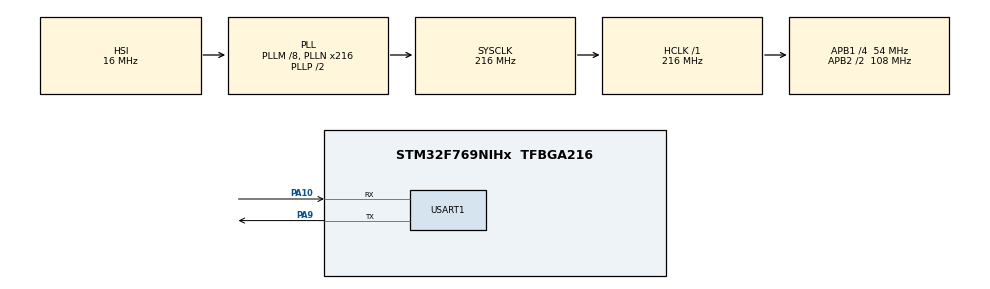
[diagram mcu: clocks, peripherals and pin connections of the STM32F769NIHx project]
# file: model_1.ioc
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CORTEX_M7.ART_ACCELERATOR_ENABLE=1
CORTEX_M7.CPU_DCache=Enabled
CORTEX_M7.CPU_ICache=Enabled
CORTEX_M7.PREFETCH_ENABLE=1
CORTEX_M7.default_mode_Activation=1
Mcu.Family=STM32F7
Mcu.Name=STM32F769NIHx
Mcu.Package=TFBGA216
NVIC.PriorityGroup=NVIC_PRIORITYGROUP_4
PA10.Mode=Asynchronous
PA10.Signal=USART1_RX
PA13.Mode=Serial_Wire
PA13.Signal=SYS_JTMS-SWDIO
PA14.Mode=Serial_Wire
PA14.Signal=SYS_JTCK-SWCLK
PA9.Mode=Asynchronous
PA9.Signal=USART1_TX
PH0/OSC_IN.Mode=HSE-External-Clock-Source
PH0/OSC_IN.Signal=RCC_OSC_IN
PH1/OSC_OUT.Mode=HSE-External-Clock-Source
PH1/OSC_OUT.Signal=RCC_OSC_OUT
ProjectManager.HeapSize=0x800
ProjectManager.StackSize=0x800
ProjectManager.TargetToolchain=STM32CubeIDE
RCC.AHBFreq_Value=216000000
RCC.APB1CLKDivider=RCC_HCLK_DIV4
RCC.APB1Freq_Value=54000000
RCC.APB1TimFreq_Value=108000000
RCC.APB2CLKDivider=RCC_HCLK_DIV2
RCC.APB2Freq_Value=108000000
RCC.APB2TimFreq_Value=216000000
RCC.CortexFreq_Value=216000000
RCC.HCLKFreq_Value=216000000
RCC.HSE_VALUE=8000000
RCC.HSI_VALUE=16000000
RCC.LSE_VALUE=32768
RCC.PLLM=8
RCC.PLLMUL=RCC_PLL_MUL9
RCC.PLLN=216
RCC.PLLQ=9
RCC.PRESCALERUSB=RCC_USBCLKSOURCE_PLL_DIV1_5
RCC.SYSCLKFreq_VALUE=216000000
RCC.SYSCLKSource=RCC_SYSCLKSOURCE_PLLCLK
RCC.SYSCLKSourceVirtual=RCC_SYSCLKSOURCE_PLLCLK
RCC.USBFreq_Value=48000000
RCC.VCOOutputFreq_Value=432000000
STMicroelectronics.X-CUBE-AI.9.0.0.ActivationBufferSizeList=120128
STMicroelectronics.X-CUBE-AI.9.0.0.ActivationBuffers=pool0
STMicroelectronics.X-CUBE-AI.9.0.0.ActivationNames=pool0
STMicroelectronics.X-CUBE-AI.9.0.0.ActivationSizes=AI_NETWORK_DATA_ACTIVATION_1_SIZE
STMicroelectronics.X-CUBE-AI.9.0.0.HeapSize=0x800
STMicroelectronics.X-CUBE-AI.9.0.0.InternalRamActivationBufferMaxSize=AI_NETWORK_DATA_ACTIVATIONS_SIZE
STMicroelectronics.X-CUBE-AI.9.0.0.LatestDirectoryUsed-00ec6f8c7ce3d0c30ca3e335a139c65a596e4951ea793adf710c689212e737b4=C\:\\Varsity\\Year of Study 4 (IE)\\Semester 2\\Investigation Project\\Project Implementation\\Code\\Experimentation\\Autoencoder
STMicroelectronics.X-CUBE-AI.9.0.0.MaximumNumberOfInputLayer=1
STMicroelectronics.X-CUBE-AI.9.0.0.MaximumNumberOfOutputLayer=1
STMicroelectronics.X-CUBE-AI.9.0.0.MaximumSizeOfInputLayer=1
STMicroelectronics.X-CUBE-AI.9.0.0.MaximumSizeOfOutputLayer=1
STMicroelectronics.X-CUBE-AI.9.0.0.ModelActualCompression-00ec6f8c7ce3d0c30ca3e335a139c65a596e4951ea793adf710c689212e737b4=0.0
STMicroelectronics.X-CUBE-AI.9.0.0.ModelCompression-00ec6f8c7ce3d0c30ca3e335a139c65a596e4951ea793adf710c689212e737b4=Medium
STMicroelectronics.X-CUBE-AI.9.0.0.ModelFlashOccupation-00ec6f8c7ce3d0c30ca3e335a139c65a596e4951ea793adf710c689212e737b4=489160
STMicroelectronics.X-CUBE-AI.9.0.0.ModelHashList=00ec6f8c7ce3d0c30ca3e335a139c65a596e4951ea793adf710c689212e737b4
STMicroelectronics.X-CUBE-AI.9.0.0.ModelKind-00ec6f8c7ce3d0c30ca3e335a139c65a596e4951ea793adf710c689212e737b4=KERAS
STMicroelectronics.X-CUBE-AI.9.0.0.ModelMacc-00ec6f8c7ce3d0c30ca3e335a139c65a596e4951ea793adf710c689212e737b4=962370
STMicroelectronics.X-CUBE-AI.9.0.0.ModelName-00ec6f8c7ce3d0c30ca3e335a139c65a596e4951ea793adf710c689212e737b4=network
STMicroelectronics.X-CUBE-AI.9.0.0.ModelNameList=network
STMicroelectronics.X-CUBE-AI.9.0.0.ModelRamOccupation-00ec6f8c7ce3d0c30ca3e335a139c65a596e4951ea793adf710c689212e737b4=120128
STMicroelectronics.X-CUBE-AI.9.0.0.ModelStructureFile-00ec6f8c7ce3d0c30ca3e335a139c65a596e4951ea793adf710c689212e737b4=C\:\\Varsity\\Year of Study 4 (IE)\\Semester 2\\Investigation Project\\Project Implementation\\Code\\Experimentation\\Autoencoder\\Cable-98-Accuracy-db-tf.keras
STMicroelectronics.X-CUBE-AI.9.0.0.ModelType-00ec6f8c7ce3d0c30ca3e335a139c65a596e4951ea793adf710c689212e737b4=STM32Cube.AI MCU runtime
STMicroelectronics.X-CUBE-AI.9.0.0.ReadyForCodeGeneration=true
STMicroelectronics.X-CUBE-AI.9.0.0.StackSize=0x800
STMicroelectronics.X-CUBE-AI.9.0.0.WorkingBufferStartAddrList=0xFFFFFFFF
STMicroelectronics.X-CUBE-AI.9.0.0.XAaCUBEAaAICcArtificialOoIntelligenceJjCore=true
STMicroelectronics.X-CUBE-AI.9.0.0.copyWeightToRam=false
STMicroelectronics.X-CUBE-AI.9.0.0.copyWeightToRam-00ec6f8c7ce3d0c30ca3e335a139c65a596e4951ea793adf710c689212e737b4=false
STMicroelectronics.X-CUBE-AI.9.0.0.customLayerConfigEnabled=false
STMicroelectronics.X-CUBE-AI.9.0.0.customLayerConfigEnabled-00ec6f8c7ce3d0c30ca3e335a139c65a596e4951ea793adf710c689212e737b4=false
STMicroelectronics.X-CUBE-AI.9.0.0.noOnnxIoTranspose=false
STMicroelectronics.X-CUBE-AI.9.0.0.noOnnxIoTranspose-00ec6f8c7ce3d0c30ca3e335a139c65a596e4951ea793adf710c689212e737b4=false
STMicroelectronics.X-CUBE-AI.9.0.0.useInputAllocation=true
STMicroelectronics.X-CUBE-AI.9.0.0.useInputAllocation-00ec6f8c7ce3d0c30ca3e335a139c65a596e4951ea793adf710c689212e737b4=true
STMicroelectronics.X-CUBE-AI.9.0.0.useOutputAllocation=true
STMicroelectronics.X-CUBE-AI.9.0.0.useOutputAllocation-00ec6f8c7ce3d0c30ca3e335a139c65a596e4951ea793adf710c689212e737b4=true
TIM14.Prescaler=107
USART1.VirtualMode-Asynchronous=VM_ASYNC
VP_CRC_VS_CRC.Mode=CRC_Activate
VP_STMicroelectronics.X-CUBE-AI_VS_ArtificialOoIntelligenceJjXAaCUBEAaAI_9.0.0.Mode=ArtificialOoIntelligenceJjXAaCUBEAaAI
VP_TIM14_VS_ClockSourceINT.Mode=Enable_Timer
board=custom

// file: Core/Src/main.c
/* USER CODE BEGIN Header */
/**
  ******************************************************************************
  * @file           : main.c
  * @brief          : Main program body
  ******************************************************************************
  * @attention
  *
  * Copyright (c) 2024 STMicroelectronics.
  * All rights reserved.
  *
  * This software is licensed under terms that can be found in the LICENSE file
  * in the root directory of this software component.
  * If no LICENSE file comes with this software, it is provided AS-IS.
  *
  ******************************************************************************
  */
/* USER CODE END Header */
#include "main.h"

/* USER CODE BEGIN Includes */
#include "network.h"
#include "network_data.h"
#include "anomaly_image_data_0.h"
#include "stdio.h"

/* USER CODE END Includes */

CRC_HandleTypeDef hcrc;

TIM_HandleTypeDef htim14;

UART_HandleTypeDef huart1;

void SystemClock_Config(void);
static void MPU_Config(void);
static void MX_GPIO_Init(void);
static void MX_CRC_Init(void);
static void MX_TIM14_Init(void);
static void MX_USART1_UART_Init(void);

/* USER CODE BEGIN 0 */

//__attribute__((section(".sdram_data"))) const float good_image_data[10][30000];

/* USER CODE END 0 */

int main(void)
{

  /* USER CODE BEGIN 1 */
	char uart_buf[50];
	int uart_buf_len = 0;
	uint16_t timer_val = 0;

  /* USER CODE END 1 */

  /* MPU Configuration--------------------------------------------------------*/
  MPU_Config();

  /* Enable the CPU Cache */

  /* Enable I-Cache---------------------------------------------------------*/
  SCB_EnableICache();

  /* Enable D-Cache---------------------------------------------------------*/
  SCB_EnableDCache();

  /* MCU Configuration--------------------------------------------------------*/

  /* Reset of all peripherals, Initializes the Flash interface and the Systick. */
  HAL_Init();

  /* Configure the system clock */
  SystemClock_Config();

  /* Initialize all configured peripherals */
  MX_GPIO_Init();
  MX_CRC_Init();
  MX_TIM14_Init();
  MX_USART1_UART_Init();
  /* USER CODE BEGIN 2 */

  // THIS IS FOR THE COMPRESSION VALUE OF LOW!!!!!!!

  static ai_handle network = AI_HANDLE_NULL;

      /* Global c-array to handle the activations buffer */
      AI_ALIGNED(32)
      static ai_u8 activations[AI_NETWORK_DATA_ACTIVATIONS_SIZE];

      /* Array to store the data of the input tensor */
      AI_ALIGNED(32)
      static ai_float in_data[AI_NETWORK_IN_1_SIZE];
      /* or static ai_u8 in_data[AI_NETWORK_IN_1_SIZE_BYTES]; */

      /* c-array to store the data of the output tensor */
      AI_ALIGNED(32)
      static ai_float out_data[AI_NETWORK_OUT_1_SIZE];
    //  static ai_u8 out_data[AI_NETWORK_OUT_1_SIZE_BYTES];

      /* Array of pointer to manage the model's input/output tensors */
      static ai_buffer *ai_input;
      static ai_buffer *ai_output;

      int aiInit(void) {
          ai_error err;

          /* Create and initialize the c-model */
          const ai_handle acts[] = { activations };
          err = ai_network_create_and_init(&network, acts, NULL);
          if (err.type != AI_ERROR_NONE) {}

          /* Reteive pointers to the model's input/output tensors */
          ai_input = ai_network_inputs_get(network, NULL);
          ai_output = ai_network_outputs_get(network, NULL);

          return 0;
        }

      int aiRun(const void *in_data, void *out_data) {
          ai_i32 n_batch;
          ai_error err;

          /* 1 - Update IO handlers with the data payload */
          ai_input[0].data = AI_HANDLE_PTR(in_data);
          ai_output[0].data = AI_HANDLE_PTR(out_data);

          /* 2 - Perform the inference */
          n_batch = ai_network_run(network, &ai_input[0], &ai_output[0]);
          if (n_batch != 1) {
              err = ai_network_get_error(network);
          };

          return 0;
        }

      int argmax(ai_float nn_output[]){

    	  if (nn_output[0] > nn_output[1]){
    		  return 0;
    	  }
    	  else{
    		  return 1;
    	  }
      }

      uint8_t counter = 0;
      int argmax_output = 0;
      float acc = 0.0;
      int true_positives = 0;
      int false_negatives = 0;

      int false_positives = 0;
      int true_negatives = 0;
      int final_outputs[3] = {0, 0, 0};

    float get_accuracy(int counter, float num_images){
    	  int count_value = counter;
    	  float accuracy = (float)(count_value/num_images);
    	  return accuracy;
      }

    void calculate_true_positives(int output[], int size){

    	for(int i = 0; i < size; i++){
    		if (output[i] == 0){
    			true_positives++;
    		}
    	}
    }

    void calculate_false_negatives(int output[], int size){

        	for(int i = 0; i < size; i++){
        		if (output[i] == 1){
        			false_negatives++;
        		}
        	}
        }

    void calculate_false_positives(int output[], int size){

            	for(int i = 0; i < size; i++){
            		if (output[i] == 0){
            			false_positives++;
            		}
            	}
            }

    void calculate_true_negatives(int output[], int size){

            	for(int i = 0; i < size; i++){
            		if (output[i] == 1){
            			true_negatives++;
            		}
            	}
            }

      aiInit();

      HAL_TIM_Base_Start(&htim14);

  /* USER CODE END 2 */

  /* Infinite loop */
  /* USER CODE BEGIN WHILE */
  while (1)
  {
	  for (int i = 0; i < 3; i++){
		  for (int j = 0; j < AI_NETWORK_IN_1_SIZE; j++){
		  	  	  		  ((ai_float*)in_data)[j] = image_data[i][j];
		  	  	  	  }

		  	  	  	  timer_val = __HAL_TIM_GET_COUNTER(&htim14);
		  	  	  	  aiRun(in_data, out_data);
		  	  	  	  timer_val = __HAL_TIM_GET_COUNTER(&htim14) - timer_val;

		  	  	  	  uart_buf_len = sprintf(uart_buf, "%u us\r\n", timer_val);
		  	  	      HAL_UART_Transmit(&huart1, (uint8_t *)uart_buf, uart_buf_len, 100);

		  	  	  	  argmax_output = argmax(out_data);
		  	  	  	  final_outputs[i] = argmax_output;

		  	  	  	  //HAL_UART_Transmit(&huart1, message, 50, HAL_MAX_DELAY);
//		  	  	  	  HAL_Delay(2000);
	  }

	  //acc = get_accuracy(counter, 5.0);

	  uart_buf_len = sprintf(uart_buf, "\r\n \r\n \r\n \r\n");
	  HAL_UART_Transmit(&huart1, (uint8_t *)uart_buf, uart_buf_len, 100);
//	  calculate_true_positives(final_outputs, 2);
//	  calculate_false_negatives(final_outputs, 2);
	  calculate_false_positives(final_outputs, 3);
	  calculate_true_negatives(final_outputs, 3);

    /* USER CODE END WHILE */

  }
}

void SystemClock_Config(void)
{
  RCC_OscInitTypeDef RCC_OscInitStruct = {0};
  RCC_ClkInitTypeDef RCC_ClkInitStruct = {0};

  /** Configure the main internal regulator output voltage
  */
  __HAL_RCC_PWR_CLK_ENABLE();
  __HAL_PWR_VOLTAGESCALING_CONFIG(PWR_REGULATOR_VOLTAGE_SCALE1);

  /** Initializes the RCC Oscillators according to the specified parameters
  * in the RCC_OscInitTypeDef structure.
  */
  RCC_OscInitStruct.OscillatorType = RCC_OSCILLATORTYPE_HSI;
  RCC_OscInitStruct.HSIState = RCC_HSI_ON;
  RCC_OscInitStruct.HSICalibrationValue = RCC_HSICALIBRATION_DEFAULT;
  RCC_OscInitStruct.PLL.PLLState = RCC_PLL_ON;
  RCC_OscInitStruct.PLL.PLLSource = RCC_PLLSOURCE_HSI;
  RCC_OscInitStruct.PLL.PLLM = 8;
  RCC_OscInitStruct.PLL.PLLN = 216;
  RCC_OscInitStruct.PLL.PLLP = RCC_PLLP_DIV2;
  RCC_OscInitStruct.PLL.PLLQ = 9;
  RCC_OscInitStruct.PLL.PLLR = 2;
  if (HAL_RCC_OscConfig(&RCC_OscInitStruct) != HAL_OK)
  {
    Error_Handler();
  }

  /** Activate the Over-Drive mode
  */
  if (HAL_PWREx_EnableOverDrive() != HAL_OK)
  {
    Error_Handler();
  }

  /** Initializes the CPU, AHB and APB buses clocks
  */
  RCC_ClkInitStruct.ClockType = RCC_CLOCKTYPE_HCLK|RCC_CLOCKTYPE_SYSCLK
                              |RCC_CLOCKTYPE_PCLK1|RCC_CLOCKTYPE_PCLK2;
  RCC_ClkInitStruct.SYSCLKSource = RCC_SYSCLKSOURCE_PLLCLK;
  RCC_ClkInitStruct.AHBCLKDivider = RCC_SYSCLK_DIV1;
  RCC_ClkInitStruct.APB1CLKDivider = RCC_HCLK_DIV4;
  RCC_ClkInitStruct.APB2CLKDivider = RCC_HCLK_DIV2;

  if (HAL_RCC_ClockConfig(&RCC_ClkInitStruct, FLASH_LATENCY_7) != HAL_OK)
  {
    Error_Handler();
  }
}

static void MX_CRC_Init(void)
{

  hcrc.Instance = CRC;
  hcrc.Init.DefaultPolynomialUse = DEFAULT_POLYNOMIAL_ENABLE;
  hcrc.Init.DefaultInitValueUse = DEFAULT_INIT_VALUE_ENABLE;
  hcrc.Init.InputDataInversionMode = CRC_INPUTDATA_INVERSION_NONE;
  hcrc.Init.OutputDataInversionMode = CRC_OUTPUTDATA_INVERSION_DISABLE;
  hcrc.InputDataFormat = CRC_INPUTDATA_FORMAT_BYTES;
  if (HAL_CRC_Init(&hcrc) != HAL_OK)
  {
    Error_Handler();
  }

}

static void MX_TIM14_Init(void)
{

  htim14.Instance = TIM14;
  htim14.Init.Prescaler = 107;
  htim14.Init.CounterMode = TIM_COUNTERMODE_UP;
  htim14.Init.Period = 65535;
  htim14.Init.ClockDivision = TIM_CLOCKDIVISION_DIV1;
  htim14.Init.AutoReloadPreload = TIM_AUTORELOAD_PRELOAD_DISABLE;
  if (HAL_TIM_Base_Init(&htim14) != HAL_OK)
  {
    Error_Handler();
  }

}

static void MX_USART1_UART_Init(void)
{

  huart1.Instance = USART1;
  huart1.Init.BaudRate = 115200;
  huart1.Init.WordLength = UART_WORDLENGTH_8B;
  huart1.Init.StopBits = UART_STOPBITS_1;
  huart1.Init.Parity = UART_PARITY_NONE;
  huart1.Init.Mode = UART_MODE_TX_RX;
  huart1.Init.HwFlowCtl = UART_HWCONTROL_NONE;
  huart1.Init.OverSampling = UART_OVERSAMPLING_16;
  huart1.Init.OneBitSampling = UART_ONE_BIT_SAMPLE_DISABLE;
  huart1.AdvancedInit.AdvFeatureInit = UART_ADVFEATURE_NO_INIT;
  if (HAL_UART_Init(&huart1) != HAL_OK)
  {
    Error_Handler();
  }

}

static void MX_GPIO_Init(void)
{

  /* GPIO Ports Clock Enable */
  __HAL_RCC_GPIOA_CLK_ENABLE();
  __HAL_RCC_GPIOH_CLK_ENABLE();

}

 /* MPU Configuration */

void MPU_Config(void)
{
  MPU_Region_InitTypeDef MPU_InitStruct = {0};

  /* Disables the MPU */
  HAL_MPU_Disable();

  /** Initializes and configures the Region and the memory to be protected
  */
  MPU_InitStruct.Enable = MPU_REGION_ENABLE;
  MPU_InitStruct.Number = MPU_REGION_NUMBER0;
  MPU_InitStruct.BaseAddress = 0x0;
  MPU_InitStruct.Size = MPU_REGION_SIZE_4GB;
  MPU_InitStruct.SubRegionDisable = 0x87;
  MPU_InitStruct.TypeExtField = MPU_TEX_LEVEL0;
  MPU_InitStruct.AccessPermission = MPU_REGION_NO_ACCESS;
  MPU_InitStruct.DisableExec = MPU_INSTRUCTION_ACCESS_DISABLE;
  MPU_InitStruct.IsShareable = MPU_ACCESS_SHAREABLE;
  MPU_InitStruct.IsCacheable = MPU_ACCESS_NOT_CACHEABLE;
  MPU_InitStruct.IsBufferable = MPU_ACCESS_NOT_BUFFERABLE;

  HAL_MPU_ConfigRegion(&MPU_InitStruct);
  /* Enables the MPU */
  HAL_MPU_Enable(MPU_PRIVILEGED_DEFAULT);

}

void Error_Handler(void)
{
  __disable_irq();
  while (1)
  {
  }
}
